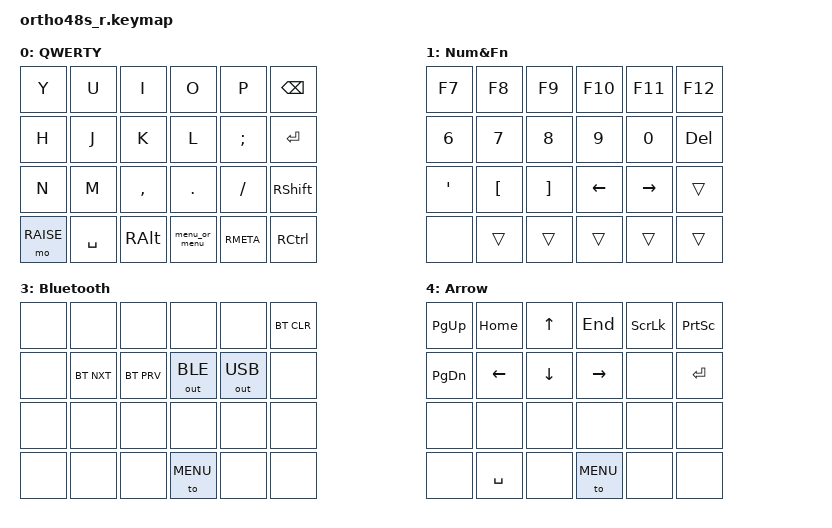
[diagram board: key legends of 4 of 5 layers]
#include <behaviors.dtsi>
#include <dt-bindings/zmk/keys.h>
#include <dt-bindings/zmk/bt.h>
#include <dt-bindings/zmk/outputs.h>

#define DEFAULT 0
#define RAISE 1
#define MENU 2
#define BLUETOOTH 3
#define ARROW 4

/ {
  behaviors {
    menu_or_menu: tap_dance_menu {
      compatible = "zmk,behavior-tap-dance";
      #binding-cells = <0>;
      tapping-term-ms = <200>;
      bindings = <&kp K_CONTEXT_MENU>, <&to MENU>;
    };
  };

  keymap {
    compatible = "zmk,keymap";

    default_layer {
      display-name = "QWERTY";
      bindings = <
        &kp Y &kp U &kp I &kp O &kp P &kp BACKSPACE
        &kp H &kp J &kp K &kp L &kp SEMICOLON &kp ENTER
        &kp N &kp M &kp COMMA &kp DOT &kp SLASH &kp RSHIFT
        &mo RAISE &kp SPACE &kp RALT &menu_or_menu &kp RMETA &kp RCTRL
      >;
    };
    raise_layer {
      display-name = "Num&Fn";
      bindings = <
        &kp F7 &kp F8 &kp F9 &kp F10 &kp F11 &kp F12
        &kp N6 &kp N7 &kp N8 &kp N9 &kp N0 &kp DELETE
        &kp APOSTROPHE &kp LEFT_BRACKET &kp RIGHT_BRACKET &kp LEFT &kp RIGHT &trans
        &none &trans &trans &trans &trans &trans
      >;
    };
    menu_layer {
      display-name = "Menu";
      bindings = <
        &sys_reset &bootloader &none &none &none &none
        &none &to DEFAULT &to BLUETOOTH &to ARROW &none
        &none &none &none &none &none &none
        &none &none &none &none &none &none
      >;
    };
    bluetooth_layer {
      display-name = "Bluetooth";
      bindings = <
        &none &none &none &none &none &bt BT_CLR
        &none &bt BT_NXT &bt BT_PRV &out OUT_BLE &out OUT_USB &none
        &none &none &none &none &none &none
        &none &none &none &to MENU &none &none
      >;
    };
    arrow_layer {
      display-name = "Arrow";
      bindings = <
        &kp PG_UP &kp HOME &kp UP &kp END &kp SCROLLLOCK &kp PRINTSCREEN
        &kp PG_DN &kp LEFT &kp DOWN &kp RIGHT &none &kp ENTER
        &none &none &none &none &none &none
        &none &kp SPACE &none &to MENU &none &none
      >;
    };
  };
};
